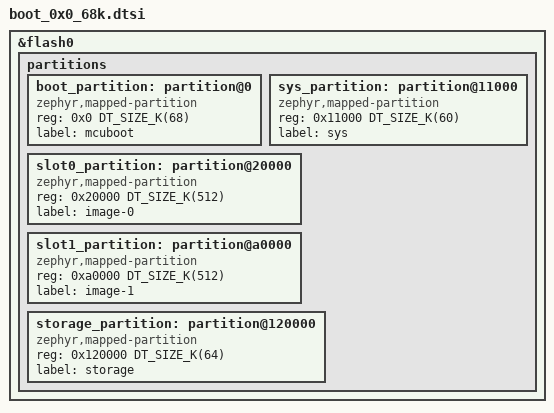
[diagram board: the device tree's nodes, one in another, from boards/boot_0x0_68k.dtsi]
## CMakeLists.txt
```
# SPDX-License-Identifier: Apache-2.0

cmake_minimum_required(VERSION 3.28.0)

find_package(Zephyr REQUIRED HINTS $ENV{ZEPHYR_BASE})
project(secure_boot)

target_sources(app PRIVATE src/main.c)
```

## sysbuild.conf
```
# A single slot keeps image authentication while dropping the swap path,
# so the MCUboot body can stay inside the ROM Secure Boot buffer.
# Sysbuild forwards this after image fragments.

SB_CONFIG_MCUBOOT_MODE_SINGLE_APP=y
```

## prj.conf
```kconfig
CONFIG_BOOTLOADER_MCUBOOT=y
CONFIG_LOG=y
```

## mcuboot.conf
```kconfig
# Keep the MCUboot image inside the ROM Secure Boot buffer.
# The size check still fails if the body grows past that limit.

CONFIG_LOG=n
CONFIG_BOOT_BANNER=n
CONFIG_SERIAL=n
CONFIG_CONSOLE=n
CONFIG_UART_CONSOLE=n
CONFIG_PRINTK=n
CONFIG_ASSERT=n
CONFIG_GPIO=n
```

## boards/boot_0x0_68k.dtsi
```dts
/*
 * Copyright (c) 2026 Espressif Systems (Shanghai) Co., Ltd.
 *
 * SPDX-License-Identifier: Apache-2.0
 *
 * boot_partition holds the Secure Boot v2 image: the ROM body limit, padded
 * to 4 KiB, plus the 4 KiB signature sector. A larger partition would not
 * raise the ROM buffer limit.
 */

&flash0 {
	/delete-node/ partitions;

	partitions {
		ranges;
		#address-cells = <1>;
		#size-cells = <1>;

		boot_partition: partition@0 {
			compatible = "zephyr,mapped-partition";
			reg = <0x0 DT_SIZE_K(68)>;
			label = "mcuboot";
		};

		sys_partition: partition@11000 {
			compatible = "zephyr,mapped-partition";
			reg = <0x11000 DT_SIZE_K(60)>;
			label = "sys";
		};

		slot0_partition: partition@20000 {
			compatible = "zephyr,mapped-partition";
			reg = <0x20000 DT_SIZE_K(512)>;
			label = "image-0";
		};

		slot1_partition: partition@a0000 {
			compatible = "zephyr,mapped-partition";
			reg = <0xa0000 DT_SIZE_K(512)>;
			label = "image-1";
		};

		storage_partition: partition@120000 {
			compatible = "zephyr,mapped-partition";
			reg = <0x120000 DT_SIZE_K(64)>;
			label = "storage";
		};
	};
};
```

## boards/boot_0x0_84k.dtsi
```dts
/*
 * Copyright (c) 2026 Espressif Systems (Shanghai) Co., Ltd.
 *
 * SPDX-License-Identifier: Apache-2.0
 *
 * boot_partition holds the Secure Boot v2 image: the ROM body limit, padded
 * to 4 KiB, plus the 4 KiB signature sector. A larger partition would not
 * raise the ROM buffer limit.
 */

&flash0 {
	/delete-node/ partitions;

	partitions {
		ranges;
		#address-cells = <1>;
		#size-cells = <1>;

		boot_partition: partition@0 {
			compatible = "zephyr,mapped-partition";
			reg = <0x0 DT_SIZE_K(84)>;
			label = "mcuboot";
		};

		sys_partition: partition@15000 {
			compatible = "zephyr,mapped-partition";
			reg = <0x15000 DT_SIZE_K(44)>;
			label = "sys";
		};

		slot0_partition: partition@20000 {
			compatible = "zephyr,mapped-partition";
			reg = <0x20000 DT_SIZE_K(512)>;
			label = "image-0";
		};

		slot1_partition: partition@a0000 {
			compatible = "zephyr,mapped-partition";
			reg = <0xa0000 DT_SIZE_K(512)>;
			label = "image-1";
		};

		storage_partition: partition@120000 {
			compatible = "zephyr,mapped-partition";
			reg = <0x120000 DT_SIZE_K(64)>;
			label = "storage";
		};
	};
};
```

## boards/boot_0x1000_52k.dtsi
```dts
/*
 * Copyright (c) 2026 Espressif Systems (Shanghai) Co., Ltd.
 *
 * SPDX-License-Identifier: Apache-2.0
 *
 * boot_partition holds the Secure Boot v2 image: the ROM body limit, padded
 * to 4 KiB, plus the 4 KiB signature sector. A larger partition would not
 * raise the ROM buffer limit.
 */

&flash0 {
	/delete-node/ partitions;

	partitions {
		ranges;
		#address-cells = <1>;
		#size-cells = <1>;

		boot_partition: partition@1000 {
			compatible = "zephyr,mapped-partition";
			reg = <0x1000 DT_SIZE_K(52)>;
			label = "mcuboot";
		};

		sys_partition: partition@10000 {
			compatible = "zephyr,mapped-partition";
			reg = <0x10000 DT_SIZE_K(64)>;
			label = "sys";
		};

		slot0_partition: partition@20000 {
			compatible = "zephyr,mapped-partition";
			reg = <0x20000 DT_SIZE_K(512)>;
			label = "image-0";
		};

		slot1_partition: partition@a0000 {
			compatible = "zephyr,mapped-partition";
			reg = <0xa0000 DT_SIZE_K(512)>;
			label = "image-1";
		};

		storage_partition: partition@120000 {
			compatible = "zephyr,mapped-partition";
			reg = <0x120000 DT_SIZE_K(64)>;
			label = "storage";
		};
	};
};
```

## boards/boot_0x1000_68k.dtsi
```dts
/*
 * Copyright (c) 2026 Espressif Systems (Shanghai) Co., Ltd.
 *
 * SPDX-License-Identifier: Apache-2.0
 *
 * boot_partition holds the Secure Boot v2 image: the ROM body limit, padded
 * to 4 KiB, plus the 4 KiB signature sector. A larger partition would not
 * raise the ROM buffer limit.
 */

&flash0 {
	/delete-node/ partitions;

	partitions {
		ranges;
		#address-cells = <1>;
		#size-cells = <1>;

		boot_partition: partition@1000 {
			compatible = "zephyr,mapped-partition";
			reg = <0x1000 DT_SIZE_K(68)>;
			label = "mcuboot";
		};

		sys_partition: partition@12000 {
			compatible = "zephyr,mapped-partition";
			reg = <0x12000 DT_SIZE_K(56)>;
			label = "sys";
		};

		slot0_partition: partition@20000 {
			compatible = "zephyr,mapped-partition";
			reg = <0x20000 DT_SIZE_K(512)>;
			label = "image-0";
		};

		slot1_partition: partition@a0000 {
			compatible = "zephyr,mapped-partition";
			reg = <0xa0000 DT_SIZE_K(512)>;
			label = "image-1";
		};

		storage_partition: partition@120000 {
			compatible = "zephyr,mapped-partition";
			reg = <0x120000 DT_SIZE_K(64)>;
			label = "storage";
		};
	};
};
```

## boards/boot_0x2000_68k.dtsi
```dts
/*
 * Copyright (c) 2026 Espressif Systems (Shanghai) Co., Ltd.
 *
 * SPDX-License-Identifier: Apache-2.0
 *
 * boot_partition holds the Secure Boot v2 image: the ROM body limit, padded
 * to 4 KiB, plus the 4 KiB signature sector. A larger partition would not
 * raise the ROM buffer limit.
 */

&flash0 {
	/delete-node/ partitions;

	partitions {
		ranges;
		#address-cells = <1>;
		#size-cells = <1>;

		boot_partition: partition@2000 {
			compatible = "zephyr,mapped-partition";
			reg = <0x2000 DT_SIZE_K(68)>;
			label = "mcuboot";
		};

		sys_partition: partition@13000 {
			compatible = "zephyr,mapped-partition";
			reg = <0x13000 DT_SIZE_K(52)>;
			label = "sys";
		};

		slot0_partition: partition@20000 {
			compatible = "zephyr,mapped-partition";
			reg = <0x20000 DT_SIZE_K(512)>;
			label = "image-0";
		};

		slot1_partition: partition@a0000 {
			compatible = "zephyr,mapped-partition";
			reg = <0xa0000 DT_SIZE_K(512)>;
			label = "image-1";
		};

		storage_partition: partition@120000 {
			compatible = "zephyr,mapped-partition";
			reg = <0x120000 DT_SIZE_K(64)>;
			label = "storage";
		};
	};
};
```

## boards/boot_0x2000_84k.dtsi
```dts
/*
 * Copyright (c) 2026 Espressif Systems (Shanghai) Co., Ltd.
 *
 * SPDX-License-Identifier: Apache-2.0
 *
 * boot_partition holds the Secure Boot v2 image: the ROM body limit, padded
 * to 4 KiB, plus the 4 KiB signature sector. A larger partition would not
 * raise the ROM buffer limit.
 */

&flash0 {
	/delete-node/ partitions;

	partitions {
		ranges;
		#address-cells = <1>;
		#size-cells = <1>;

		boot_partition: partition@2000 {
			compatible = "zephyr,mapped-partition";
			reg = <0x2000 DT_SIZE_K(84)>;
			label = "mcuboot";
		};

		sys_partition: partition@17000 {
			compatible = "zephyr,mapped-partition";
			reg = <0x17000 DT_SIZE_K(36)>;
			label = "sys";
		};

		slot0_partition: partition@20000 {
			compatible = "zephyr,mapped-partition";
			reg = <0x20000 DT_SIZE_K(512)>;
			label = "image-0";
		};

		slot1_partition: partition@a0000 {
			compatible = "zephyr,mapped-partition";
			reg = <0xa0000 DT_SIZE_K(512)>;
			label = "image-1";
		};

		storage_partition: partition@120000 {
			compatible = "zephyr,mapped-partition";
			reg = <0x120000 DT_SIZE_K(64)>;
			label = "storage";
		};
	};
};
```

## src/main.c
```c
/*
 * Copyright (c) 2026 Espressif Systems (Shanghai) Co., Ltd.
 *
 * SPDX-License-Identifier: Apache-2.0
 */

#include <zephyr/kernel.h>
#include <zephyr/sys/printk.h>

int main(void)
{
	printk("Espressif Secure Boot v2 sample\n");
	return 0;
}
```
